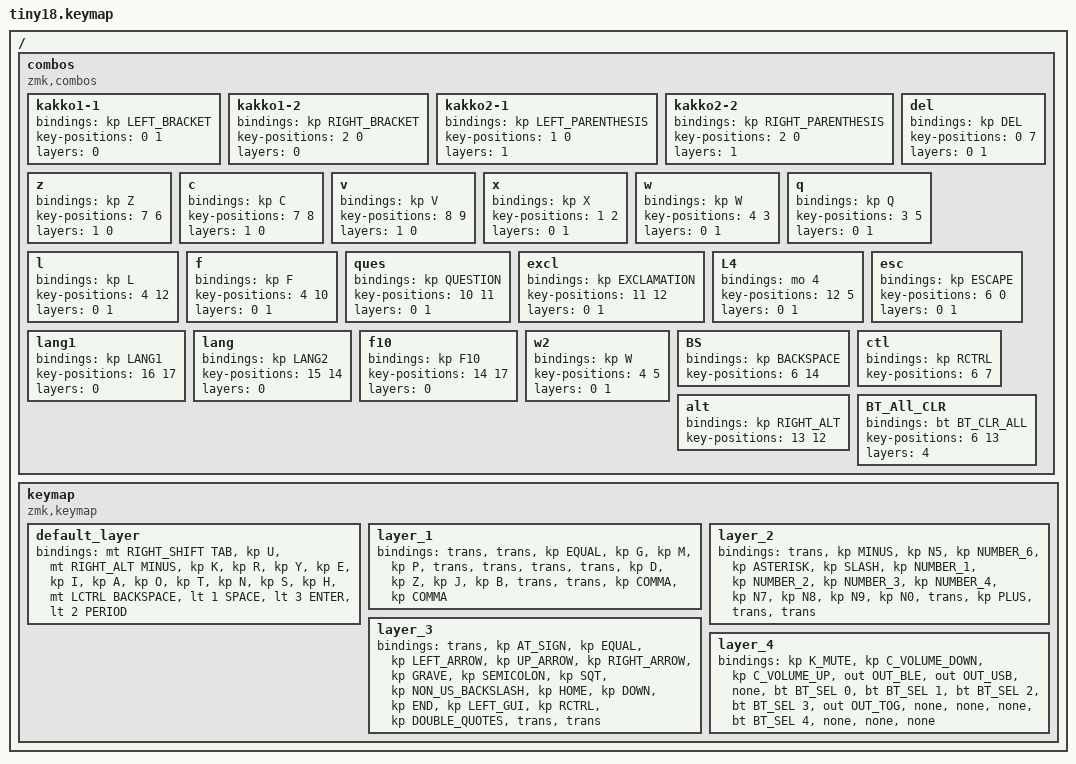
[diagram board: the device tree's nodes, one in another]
#include <input/processors.dtsi>
#include <dt-bindings/zmk/input_transform.h>
#include <zephyr/dt-bindings/input/input-event-codes.h>
#include <behaviors.dtsi>
#include <dt-bindings/zmk/bt.h>
#include <dt-bindings/zmk/keys.h>

/ {
    combos {
        compatible = "zmk,combos";

        kakko1-1 {
            bindings = <&kp LEFT_BRACKET>;
            key-positions = <0 1>;
            layers = <0>;
        };

        kakko1-2 {
            bindings = <&kp RIGHT_BRACKET>;
            key-positions = <2 0>;
            layers = <0>;
        };

        kakko2-1 {
            bindings = <&kp LEFT_PARENTHESIS>;
            key-positions = <1 0>;
            layers = <1>;
        };

        kakko2-2 {
            bindings = <&kp RIGHT_PARENTHESIS>;
            key-positions = <2 0>;
            layers = <1>;
        };

        del {
            bindings = <&kp DEL>;
            key-positions = <0 7>;
            layers = <0 1>;
        };

        z {
            bindings = <&kp Z>;
            key-positions = <7 6>;
            layers = <1 0>;
        };

        c {
            bindings = <&kp C>;
            key-positions = <7 8>;
            layers = <1 0>;
        };

        v {
            bindings = <&kp V>;
            key-positions = <8 9>;
            layers = <1 0>;
        };

        x {
            bindings = <&kp X>;
            key-positions = <1 2>;
            layers = <0 1>;
        };

        w {
            bindings = <&kp W>;
            key-positions = <4 3>;
            layers = <0 1>;
        };

        q {
            bindings = <&kp Q>;
            key-positions = <3 5>;
            layers = <0 1>;
        };

        l {
            bindings = <&kp L>;
            key-positions = <4 12>;
            layers = <0 1>;
        };

        f {
            bindings = <&kp F>;
            key-positions = <4 10>;
            layers = <0 1>;
        };

        ques {
            bindings = <&kp QUESTION>;
            key-positions = <10 11>;
            layers = <0 1>;
        };

        excl {
            bindings = <&kp EXCLAMATION>;
            key-positions = <11 12>;
            layers = <0 1>;
        };

        L4 {
            bindings = <&mo 4>;
            key-positions = <12 5>;
            layers = <0 1>;
        };

        esc {
            bindings = <&kp ESCAPE>;
            key-positions = <6 0>;
            layers = <0 1>;
        };

        lang1 {
            bindings = <&kp LANG1>;
            key-positions = <16 17>;
            layers = <0>;
        };

        lang {
            bindings = <&kp LANG2>;
            key-positions = <15 14>;
            layers = <0>;
        };

        f10 {
            bindings = <&kp F10>;
            key-positions = <14 17>;
            layers = <0>;
        };

        w2 {
            bindings = <&kp W>;
            key-positions = <4 5>;
            layers = <0 1>;
        };

        BS {
            bindings = <&kp BACKSPACE>;
            key-positions = <6 14>;
        };

        ctl {
            bindings = <&kp RCTRL>;
            key-positions = <6 7>;
        };

        alt {
            bindings = <&kp RIGHT_ALT>;
            key-positions = <13 12>;
        };

        BT_All_CLR {
            bindings = <&bt BT_CLR_ALL>;
            key-positions = <6 13>;
            layers = <4>;
        };
    };

    keymap {
        compatible = "zmk,keymap";

        default_layer {
            bindings = <
&mt RIGHT_SHIFT TAB  &kp U  &mt RIGHT_ALT MINUS  &kp K  &kp R  &kp Y  &kp E  &kp I  &kp A  &kp O  &kp T  &kp N  &kp S  &kp H  &mt LCTRL BACKSPACE  &lt 1 SPACE  &lt 3 ENTER  &lt 2 PERIOD
            >;
        };

        layer_1 {
            bindings = <
&trans  &trans  &kp EQUAL  &kp G  &kp M  &kp P  &trans  &trans  &trans  &trans  &kp D  &kp Z  &kp J  &kp B  &trans  &trans  &kp COMMA  &kp COMMA
            >;
        };

        layer_2 {
            bindings = <
&trans  &kp MINUS  &kp N5  &kp NUMBER_6  &kp ASTERISK  &kp SLASH  &kp NUMBER_1  &kp NUMBER_2  &kp NUMBER_3  &kp NUMBER_4  &kp N7  &kp N8  &kp N9  &kp N0  &trans  &kp PLUS  &trans  &trans
            >;
        };

        layer_3 {
            bindings = <
&trans  &kp AT_SIGN  &kp EQUAL  &kp LEFT_ARROW  &kp UP_ARROW  &kp RIGHT_ARROW  &kp GRAVE  &kp SEMICOLON  &kp SQT  &kp NON_US_BACKSLASH  &kp HOME  &kp DOWN  &kp END  &kp LEFT_GUI  &kp RCTRL  &kp DOUBLE_QUOTES  &trans  &trans
            >;
        };

        layer_4 {
            bindings = <
&kp K_MUTE  &kp C_VOLUME_DOWN  &kp C_VOLUME_UP  &out OUT_BLE  &out OUT_USB  &none  &bt BT_SEL 0  &bt BT_SEL 1  &bt BT_SEL 2  &bt BT_SEL 3  &out OUT_TOG  &none  &none  &none  &bt BT_SEL 4  &none  &none  &none
            >;
        };
    };
};
